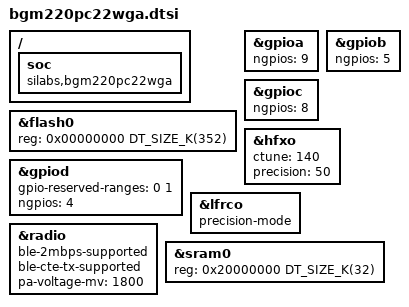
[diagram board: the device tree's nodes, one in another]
/*
 * Copyright (c) 2025 Silicon Laboratories Inc.
 *
 * SPDX-License-Identifier: Apache-2.0
 */

#include <mem.h>
#include <silabs/xg22/bgm22.dtsi>

/ {
	soc {
		compatible = "silabs,bgm220pc22wga", "silabs,bgm22", "silabs,xg22", "silabs,efr32",
			     "simple-bus";
	};
};

&flash0 {
	reg = <0x00000000 DT_SIZE_K(352)>;
};

&gpioa {
	ngpios = <9>;
};

&gpiob {
	ngpios = <5>;
};

&gpioc {
	ngpios = <8>;
};

&gpiod {
	gpio-reserved-ranges = <0 1>;
	ngpios = <4>;
};

&hfxo {
	ctune = <140>;
	precision = <50>;
	status = "okay";
};

&lfrco {
	precision-mode;
};

&radio {
	ble-2mbps-supported;
	ble-cte-tx-supported;
	pa-voltage-mv = <1800>;
};

&sram0 {
	reg = <0x20000000 DT_SIZE_K(32)>;
};
